# SAM9X75D5MN0 register map
Vendor: Microchip Technology; Series: SAM9X7; File version: 0
Registers are 32-bit, read-write, reset 0x0 unless marked. A register's access mark holds for its fields unless they carry their own. Offsets are from the block's base; [hi:lo] are bit positions; {n}, {i} and the like mark numbered series; 'fields as' and 'values as' point back to an identical list.

## SDMMC0 — Secure Digital MultiMedia Card Controller
Base 0x80000000; register names take the prefix SDMMC_
Same registers: SDMMC1 0x90000000
0x00 SSAR — SDMA System Address / Argument 2 Register
  [31:0] ADDR — SDMA System Address
0x00 SSAR_CMD23_MODE (alternate view of SSAR) — SDMA System Address / Argument 2 Register
  [31:0] ARG2 — SDMA Argument 2
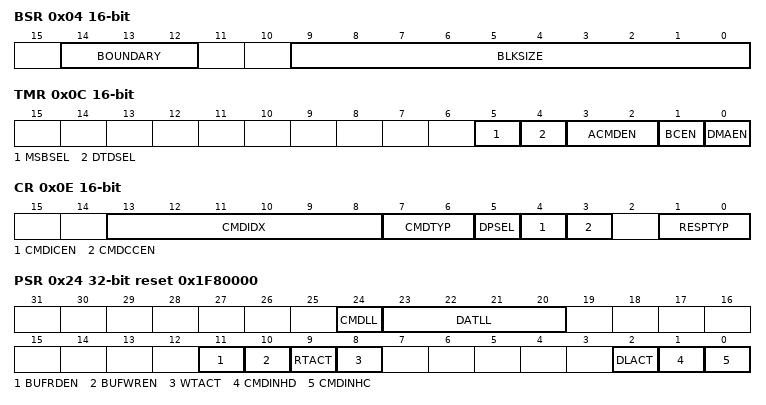
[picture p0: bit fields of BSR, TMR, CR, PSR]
0x04 BSR 16-bit — Block Size Register
  [14:12] BOUNDARY — SDMA Buffer Boundary
    0=4K (4-Kbyte boundary); 1=8K (8-Kbyte boundary); 2=16K (16-Kbyte boundary); 3=32K (32-Kbyte boundary); 4=64K (64-Kbyte boundary); 5=128K (128-Kbyte boundary); 6=256-Kbyte boundary; 7=512K (512-Kbyte boundary)
  [9:0] BLKSIZE — Transfer Block Size
0x06 BCR 16-bit — Block Count Register
  [15:0] BLKCNT — Block Count for Current Transfer
0x08 ARG1R — Argument 1 Register
  [31:0] ARG1 — Argument 1
0x0C TMR 16-bit — Transfer Mode Register
  [5] MSBSEL — Multi/Single Block Selection
  [4] DTDSEL — Data Transfer Direction Selection
    0=WRITE (Writes data from the SDMMC to the device.); 1=READ (Reads data from the device to the SDMMC.)
  [3:2] ACMDEN — Auto Command Enable
    0=DISABLED (Auto Command Disabled); 1=CMD12 (Auto CMD12 Enabled); 2=CMD23 (Auto CMD23 Enabled)
  [1] BCEN — Block Count Enable
    0=DISABLED (Block count is disabled.); 1=ENABLED (Block count is enabled.)
  [0] DMAEN — DMA Enable
    0=DISABLED (DMA functionality is disabled.); 1=ENABLED (DMA functionality is enabled.)
0x0E CR 16-bit — Command Register
  [13:8] CMDIDX — Command Index
  [7:6] CMDTYP — Command Type
    0=NORMAL (Other commands); 1=SUSPEND (CMD52 to write 'Bus Suspend' in the Card Common Control Registers (CCCR) (for SDIO only)); 2=RESUME (CMD52 to write 'Function Select' in the Card Common Control Registers (CCCR) (for SDIO only)); 3=ABORT (CMD12, CMD52 to write 'I/O Abort' in the Card Common Control Registers (CCCR) (for SDIO only))
  [5] DPSEL — Data Present Select
    0=No data present; 1=Data present
  [4] CMDICEN — Command Index Check Enable
    0=DISABLED (The Command Index Check is disabled.); 1=ENABLED (The Command Index Check is enabled.)
  [3] CMDCCEN — Command CRC Check Enable
    0=DISABLED (The Command CRC Check is disabled.); 1=ENABLED (The Command CRC Check is enabled.)
  [1:0] RESPTYP — Response Type
    0=NORESP (No Response); 1=RL136 (Response Length 136); 2=RL48 (Response Length 48); 3=RL48BUSY (Response Length 48 with Busy)
{0x10+4i} RR[{i}] (i=0..3) ro — Response Register x
  [31:0] CMDRESP — Command Response
0x20 BDPR — Buffer Data Port Register
  [31:0] BUFDATA — Buffer Data
0x24 PSR ro reset 0x1F80000 — Present State Register
  [24] CMDLL — CMD Line Level
  [23:20] DATLL — DAT[3:0] Line Level
  [11] BUFRDEN — Buffer Read Enable
  [10] BUFWREN — Buffer Write Enable
  [9] RTACT — Read Transfer Active
  [8] WTACT — Write Transfer Active
  [2] DLACT — DAT Line Active
    0=DAT line inactive; 1=DAT line active
  [1] CMDINHD — Command Inhibit (DAT)
    0=Can issue a command which uses the DAT line(s); 1=Cannot issue a command which uses the DAT line(s)
  [0] CMDINHC — Command Inhibit (CMD)
    0=Can issue a command using only CMD line; 1=Cannot issue a command
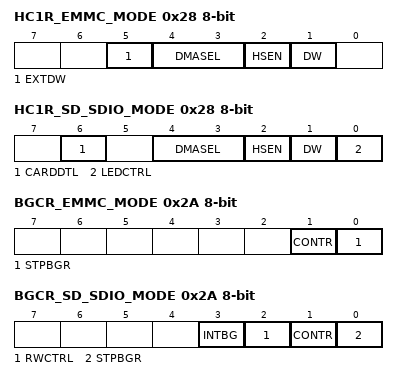
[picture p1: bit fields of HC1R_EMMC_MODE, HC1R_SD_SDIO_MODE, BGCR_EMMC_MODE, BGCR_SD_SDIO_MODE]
0x28 HC1R_EMMC_MODE 8-bit — Host Control 1 Register
  [5] EXTDW — Extended Data Width
  [4:3] DMASEL — DMA Select
    0=SDMA (SDMA is selected); 2=ADMA32 (32-bit Address ADMA2 is selected)
  [2] HSEN — High Speed Enable
  [1] DW — Data Width
    0=_1_BIT (1-bit mode.); 1=_4_BIT (4-bit mode.)
0x28 HC1R_SD_SDIO_MODE 8-bit (alternate view of HC1R_EMMC_MODE) — Host Control 1 Register
  [6] CARDDTL — Card Detect Test Level
    0=No card; 1=Card inserted
  [4:3] DMASEL — DMA Select
    values as HC1R_EMMC_MODE.DMASEL
  [2] HSEN — High Speed Enable
    0=Normal Speed mode; 1=High Speed mode
  [1] DW — Data Width
    0=1_BIT (1-bit mode.); 1=4_BIT (4-bit mode.)
  [0] LEDCTRL — LED Control
    0=OFF (LED off.); 1=ON (LED on.)
0x29 PCR 8-bit reset 0xE — Power Control Register
  [0] SDBPWR — SD Bus Power
0x2A BGCR_EMMC_MODE 8-bit — Block Gap Control Register
  [1] CONTR — Continue Request
    0=No effect; 1=Restart
  [0] STPBGR — Stop At Block Gap Request
    0=Transfer; 1=Stop
0x2A BGCR_SD_SDIO_MODE 8-bit (alternate view of BGCR_EMMC_MODE) — Block Gap Control Register
  [3] INTBG — Interrupt at Block Gap
    0=DISABLED (Interrupt detection disabled.); 1=ENABLED (Interrupt detection enabled.)
  [2] RWCTRL — Read Wait Control
    0=Disables Read Wait control; 1=Enables Read Wait control
  [1] CONTR — Continue Request
    0=No effect; 1=Restart
  [0] STPBGR — Stop At Block Gap Request
    0=Transfer; 1=Stop
0x2B WCR 8-bit — Wakeup Control Register
  [0] WKENCINT — Wakeup Event Enable on Card Interrupt
    0=DISABLED (Wakeup Event disabled.); 1=ENABLED (Wakeup Event enabled.)
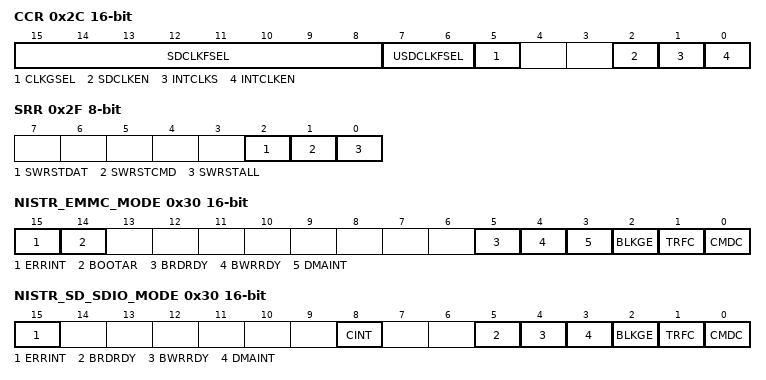
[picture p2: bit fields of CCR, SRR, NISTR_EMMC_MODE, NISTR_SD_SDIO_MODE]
0x2C CCR 16-bit — Clock Control Register
  [15:8] SDCLKFSEL — SDCLK Frequency Select
  [7:6] USDCLKFSEL — Upper Bits of SDCLK Frequency Select
  [5] CLKGSEL — Clock Generator Select
    0=Divided Clock mode (BASECLK is used to generate SDCLK); 1=Programmable Clock mode (MULTCLK is used to generate SDCLK)
  [2] SDCLKEN — SD Clock Enable
    0=SD Clock disabled; 1=SD Clock enabled
  [1] INTCLKS — Internal Clock Stable
    0=Internal clock not ready; 1=Internal clock ready
  [0] INTCLKEN — Internal Clock Enable
    0=The internal clock stops; 1=The internal clock oscillates
0x2E TCR 8-bit — Timeout Control Register
  [3:0] DTCVAL — Data Timeout Counter Value
0x2F SRR 8-bit — Software Reset Register
  [all] fields
    0=Work; 1=Reset
  [2] SWRSTDAT — Software reset for DAT line
  [1] SWRSTCMD — Software reset for CMD line
  [0] SWRSTALL — Software reset for All
0x30 NISTR_EMMC_MODE 16-bit — Normal Interrupt Status Register
  [15] ERRINT — Error Interrupt
    0=No error; 1=Error
  [14] BOOTAR — Boot Acknowledge Received
    0=Boot Acknowledge pattern not received; 1=Boot Acknowledge pattern received
  [5] BRDRDY — Buffer Read Ready
    0=Not ready to read buffer; 1=Ready to read buffer
  [4] BWRRDY — Buffer Write Ready
    0=Not ready to write buffer; 1=Ready to write buffer
  [3] DMAINT — DMA Interrupt
    0=No DMA interrupt; 1=DMA interrupt
  [2] BLKGE — Block Gap Event
  [1] TRFC — Transfer Complete
    0=Command execution is not complete; 1=Command execution is complete
  [0] CMDC — Command Complete
0x30 NISTR_SD_SDIO_MODE 16-bit (alternate view of NISTR_EMMC_MODE) — Normal Interrupt Status Register
  [15] ERRINT — Error Interrupt
  [8] CINT — Card Interrupt
    0=No card interrupt; 1=Card interrupt
  [5] BRDRDY — Buffer Read Ready
  [4] BWRRDY — Buffer Write Ready
  [3] DMAINT — DMA Interrupt
    0=No DMA Interrupt; 1=DMA Interrupt
  [2] BLKGE — Block Gap Event
    0=No block gap event; 1=Transaction stopped at block gap
  [1] TRFC — Transfer Complete
    values as NISTR_EMMC_MODE.TRFC
  [0] CMDC — Command Complete
    0=No command complete; 1=Command complete
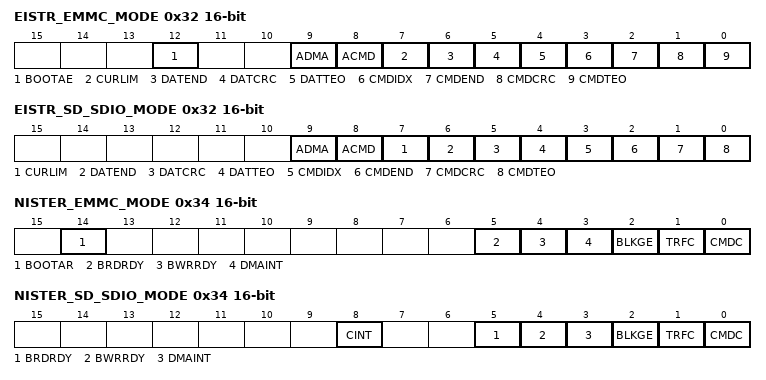
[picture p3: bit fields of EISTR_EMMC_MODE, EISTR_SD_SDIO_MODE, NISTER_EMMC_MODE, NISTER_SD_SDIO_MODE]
0x32 EISTR_EMMC_MODE 16-bit — Error Interrupt Status Register
  [12] BOOTAE — Boot Acknowledge Error
    0=No error; 1=Error
  [9] ADMA — ADMA Error
    0=No error; 1=Error
  [8] ACMD — Auto CMD Error
    0=No error; 1=Error
  [7] CURLIM — Current Limit Error
    0=No error; 1=Error
  [6] DATEND — Data End Bit Error
    0=No error; 1=Error
  [5] DATCRC — Data CRC Error
    0=No error; 1=Error
  [4] DATTEO — Data Timeout error
    0=No error; 1=Error
  [3] CMDIDX — Command Index Error
  [2] CMDEND — Command End Bit Error
  [1] CMDCRC — Command CRC Error
  [0] CMDTEO — Command Timeout Error
0x32 EISTR_SD_SDIO_MODE 16-bit (alternate view of EISTR_EMMC_MODE) — Error Interrupt Status Register
  [9] ADMA — ADMA Error
  [8] ACMD — Auto CMD Error
  [7] CURLIM — Current Limit Error
  [6] DATEND — Data End Bit Error
  [5] DATCRC — Data CRC error
    0=No error; 1=Error
  [4] DATTEO — Data Timeout Error
    0=No error; 1=Error
  [3] CMDIDX — Command Index Error
    0=No error; 1=Error
  [2] CMDEND — Command End Bit Error
    0=No error; 1=Error
  [1] CMDCRC — Command CRC Error
  [0] CMDTEO — Command Timeout Error
0x34 NISTER_EMMC_MODE 16-bit — Normal Interrupt Status Enable Register
  [14] BOOTAR — Boot Acknowledge Received Status Enable
    0=MASKED (The BOOTAR status flag in SDMMC_NISTR is masked.); 1=ENABLED (The BOOTAR status flag in SDMMC_NISTR is enabled.)
  [5] BRDRDY — Buffer Read Ready Status Enable
    0=MASKED (The BRDRDY status flag in SDMMC_NISTR is masked.); 1=ENABLED (The BRDRDY status flag in SDMMC_NISTR is enabled.)
  [4] BWRRDY — Buffer Write Ready Status Enable
    0=MASKED (The BWRRDY status flag in SDMMC_NISTR is masked.); 1=ENABLED (The BWRRDY status flag in SDMMC_NISTR is enabled.)
  [3] DMAINT — DMA Interrupt Status Enable
    0=MASKED (The DMAINT status flag in SDMMC_NISTR is masked.); 1=ENABLED (The DMAINT status flag in SDMMC_NISTR is enabled.)
  [2] BLKGE — Block Gap Event Status Enable
    0=MASKED (The BLKGE status flag in SDMMC_NISTR is masked.); 1=ENABLED (The BLKGE status flag in SDMMC_NISTR is enabled.)
  [1] TRFC — Transfer Complete Status Enable
    0=MASKED (The TRFC status flag in SDMMC_NISTR is masked.); 1=ENABLED (The TRFC status flag in SDMMC_NISTR is enabled.)
  [0] CMDC — Command Complete Status Enable
    0=MASKED (The CMDC status flag in SDMMC_NISTR is masked.); 1=ENABLED (The CMDC status flag in SDMMC_NISTR is enabled.)
0x34 NISTER_SD_SDIO_MODE 16-bit (alternate view of NISTER_EMMC_MODE) — Normal Interrupt Status Enable Register
  [8] CINT — Card Interrupt Status Enable
    0=MASKED (The CINT status flag in SDMMC_NISTR is masked.); 1=ENABLED (The CINT status flag in SDMMC_NISTR is enabled.)
  [5] BRDRDY — Buffer Read Ready Status Enable
    values as NISTER_EMMC_MODE.BRDRDY
  [4] BWRRDY — Buffer Write Ready Status Enable
    values as NISTER_EMMC_MODE.BWRRDY
  [3] DMAINT — DMA Interrupt Status Enable
    values as NISTER_EMMC_MODE.DMAINT
  [2] BLKGE — Block Gap Event Status Enable
    values as NISTER_EMMC_MODE.BLKGE
  [1] TRFC — Transfer Complete Status Enable
    values as NISTER_EMMC_MODE.TRFC
  [0] CMDC — Command Complete Status Enable
    values as NISTER_EMMC_MODE.CMDC
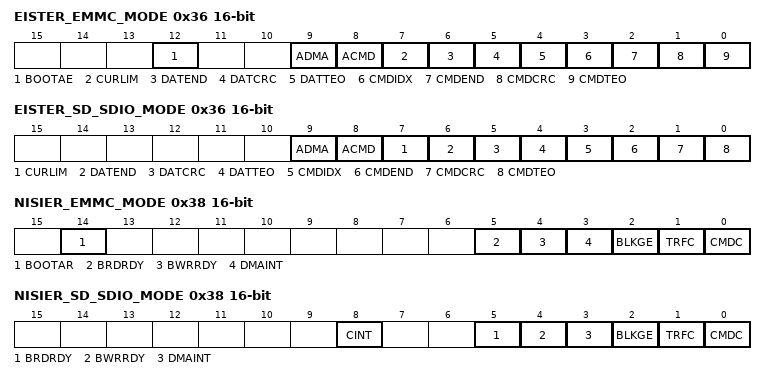
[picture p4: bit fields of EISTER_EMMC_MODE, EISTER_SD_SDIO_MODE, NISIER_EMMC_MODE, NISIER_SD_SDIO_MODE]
0x36 EISTER_EMMC_MODE 16-bit — Error Interrupt Status Enable Register
  [12] BOOTAE — Boot Acknowledge Error Status Enable
    0=MASKED (The BOOTAE status flag in SDMMC_EISTR is masked.); 1=ENABLED (The BOOTAE status flag in SDMMC_EISTR is enabled.)
  [9] ADMA — ADMA Error Status Enable
    0=MASKED (The ADMA status flag in SDMMC_EISTR is masked.); 1=ENABLED (The ADMA status flag in SDMMC_EISTR is enabled.)
  [8] ACMD — Auto CMD Error Status Enable
    0=MASKED (The ACMD status flag in SDMMC_EISTR is masked.); 1=ENABLED (The ACMD status flag in SDMMC_EISTR is enabled.)
  [7] CURLIM — Current Limit Error Status Enable
    0=MASKED (The CURLIM status flag in SDMMC_EISTR is masked.); 1=ENABLED (The CURLIM status flag in SDMMC_EISTR is enabled.)
  [6] DATEND — Data End Bit Error Status Enable
    0=MASKED (The DATEND status flag in SDMMC_EISTR is masked.); 1=ENABLED (The DATEND status flag in SDMMC_EISTR is enabled.)
  [5] DATCRC — Data CRC Error Status Enable
    0=MASKED (The DATCRC status flag in SDMMC_EISTR is masked.); 1=ENABLED (The DATCRC status flag in SDMMC_EISTR is enabled.)
  [4] DATTEO — Data Timeout Error Status Enable
    0=MASKED (The DATTEO status flag in SDMMC_EISTR is masked.); 1=ENABLED (The DATTEO status flag in SDMMC_EISTR is enabled.)
  [3] CMDIDX — Command Index Error Status Enable
    0=MASKED (The CMDIDX status flag in SDMMC_EISTR is masked.); 1=ENABLED (The CMDIDX status flag in SDMMC_EISTR is enabled.)
  [2] CMDEND — Command End Bit Error Status Enable
    0=MASKED (The CMDEND status flag in SDMMC_EISTR is masked.); 1=ENABLED (The CMDEND status flag in SDMMC_EISTR is enabled.)
  [1] CMDCRC — Command CRC Error Status Enable
    0=MASKED (The CMDCRC status flag in SDMMC_EISTR is masked.); 1=ENABLED (The CMDCRC status flag in SDMMC_EISTR is enabled.)
  [0] CMDTEO — Command Timeout Error Status Enable
    0=MASKED (The CMDTEO status flag in SDMMC_EISTR is masked.); 1=ENABLED (The CMDTEO status flag in SDMMC_EISTR is enabled.)
0x36 EISTER_SD_SDIO_MODE 16-bit (alternate view of EISTER_EMMC_MODE) — Error Interrupt Status Enable Register
  [9] ADMA — ADMA Error Status Enable
    values as EISTER_EMMC_MODE.ADMA
  [8] ACMD — Auto CMD Error Status Enable
    values as EISTER_EMMC_MODE.ACMD
  [7] CURLIM — Current Limit Error Status Enable
    values as EISTER_EMMC_MODE.CURLIM
  [6] DATEND — Data End Bit Error Status Enable
    values as EISTER_EMMC_MODE.DATEND
  [5] DATCRC — Data CRC Error Status Enable
    values as EISTER_EMMC_MODE.DATCRC
  [4] DATTEO — Data Timeout Error Status Enable
    values as EISTER_EMMC_MODE.DATTEO
  [3] CMDIDX — Command Index Error Status Enable
    values as EISTER_EMMC_MODE.CMDIDX
  [2] CMDEND — Command End Bit Error Status Enable
    values as EISTER_EMMC_MODE.CMDEND
  [1] CMDCRC — Command CRC Error Status Enable
    values as EISTER_EMMC_MODE.CMDCRC
  [0] CMDTEO — Command Timeout Error Status Enable
    values as EISTER_EMMC_MODE.CMDTEO
0x38 NISIER_EMMC_MODE 16-bit — Normal Interrupt Signal Enable Register
  [14] BOOTAR — Boot Acknowledge Received Signal Enable
    0=MASKED (No interrupt is generated when the BOOTAR status rises in SDMMC_NISTR.); 1=ENABLED (An interrupt is generated when the BOOTAR status rises in SDMMC_NISTR.)
  [5] BRDRDY — Buffer Read Ready Signal Enable
    0=MASKED (No interrupt is generated when the BRDRDY status rises in SDMMC_NISTR.); 1=ENABLED (An interrupt is generated when the BRDRDY status rises in SDMMC_NISTR.)
  [4] BWRRDY — Buffer Write Ready Signal Enable
    0=MASKED (No interrupt is generated when the BWRRDY status rises in SDMMC_NISTR.); 1=ENABLED (An interrupt is generated when the BWRRDY status rises in SDMMC_NISTR.)
  [3] DMAINT — DMA Interrupt Signal Enable
    0=MASKED (No interrupt is generated when the DMAINT status rises in SDMMC_NISTR.); 1=ENABLED (An interrupt is generated when the DMAINT status rises in SDMMC_NISTR.)
  [2] BLKGE — Block Gap Event Signal Enable
    0=MASKED (No interrupt is generated when the BLKGE status rises in SDMMC_NISTR.); 1=ENABLED (An interrupt is generated when the BLKGE status rises in SDMMC_NISTR.)
  [1] TRFC — Transfer Complete Signal Enable
    0=MASKED (No interrupt is generated when the TRFC status rises in SDMMC_NISTR.); 1=ENABLED (An interrupt is generated when the TRFC status rises in SDMMC_NISTR.)
  [0] CMDC — Command Complete Signal Enable
    0=MASKED (No interrupt is generated when the CMDC status rises in SDMMC_NISTR.); 1=ENABLED (An interrupt is generated when the CMDC status rises in SDMMC_NISTR.)
0x38 NISIER_SD_SDIO_MODE 16-bit (alternate view of NISIER_EMMC_MODE) — Normal Interrupt Signal Enable Register
  [8] CINT — Card Interrupt Signal Enable
    0=MASKED (No interrupt is generated when the CINT status rises in SDMMC_NISTR.); 1=ENABLED (An interrupt is generated when the CINT status rises in SDMMC_NISTR.)
  [5] BRDRDY — Buffer Read Ready Signal Enable
    values as NISIER_EMMC_MODE.BRDRDY
  [4] BWRRDY — Buffer Write Ready Signal Enable
    values as NISIER_EMMC_MODE.BWRRDY
  [3] DMAINT — DMA Interrupt Signal Enable
    values as NISIER_EMMC_MODE.DMAINT
  [2] BLKGE — Block Gap Event Signal Enable
    values as NISIER_EMMC_MODE.BLKGE
  [1] TRFC — Transfer Complete Signal Enable
    values as NISIER_EMMC_MODE.TRFC
  [0] CMDC — Command Complete Signal Enable
    values as NISIER_EMMC_MODE.CMDC
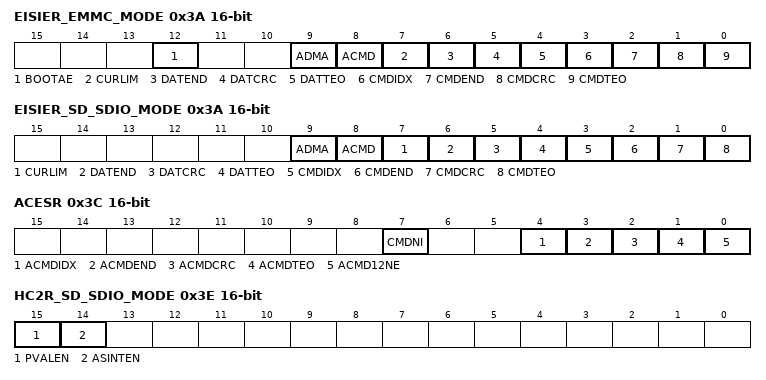
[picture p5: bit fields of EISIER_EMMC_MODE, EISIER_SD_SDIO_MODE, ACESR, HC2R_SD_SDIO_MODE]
0x3A EISIER_EMMC_MODE 16-bit — Error Interrupt Signal Enable Register
  [12] BOOTAE — Boot Acknowledge Error Signal Enable
    0=MASKED (No interrupt is generated when the BOOTAE status rises in SDMMC_EISTR.); 1=ENABLED (An interrupt is generated when the BOOTAE status rises in SDMMC_EISTR.)
  [9] ADMA — ADMA Error Signal Enable
    0=MASKED (No interrupt is generated when the ADMA status rises in SDMMC_EISTR.); 1=ENABLED (An interrupt is generated when the ADMA status rises in SDMMC_EISTR.)
  [8] ACMD — Auto CMD Error Signal Enable
    0=MASKED (No interrupt is generated when the ACMD status rises in SDMMC_EISTR.); 1=ENABLED (An interrupt is generated when the ACMD status rises in SDMMC_EISTR.)
  [7] CURLIM — Current Limit Error Signal Enable
    0=MASKED (No interrupt is generated when the CURLIM status rises in SDMMC_EISTR.); 1=ENABLED (An interrupt is generated when the CURLIM status rises in SDMMC_EISTR.)
  [6] DATEND — Data End Bit Error Signal Enable
    0=MASKED (No interrupt is generated when the DATEND status rises in SDMMC_EISTR.); 1=ENABLED (An interrupt is generated when the DATEND status rises in SDMMC_EISTR.)
  [5] DATCRC — Data CRC Error Signal Enable
    0=MASKED (No interrupt is generated when the DATCRC status rises in SDMMC_EISTR.); 1=ENABLED (An interrupt is generated when the DATCRC status rises in SDMMC_EISTR.)
  [4] DATTEO — Data Timeout Error Signal Enable
    0=MASKED (No interrupt is generated when the DATTEO status rises in SDMMC_EISTR.); 1=ENABLED (An interrupt is generated when the DATTEO status rises in SDMMC_EISTR.)
  [3] CMDIDX — Command Index Error Signal Enable
    0=MASKED (No interrupt is generated when the CMDIDX status rises in SDMMC_EISTR.); 1=ENABLED (An interrupt is generated when the CMDIDX status rises in SDMMC_EISTR.)
  [2] CMDEND — Command End Bit Error Signal Enable
    0=MASKED (No interrupt is generated when the CMDEND status rises in SDMMC_EISTR.); 1=ENABLED (An interrupt is generated when the CMDEND status rises in SDMMC_EISTR.)
  [1] CMDCRC — Command CRC Error Signal Enable
    0=MASKED (No interrupt is generated when the CDMCRC status rises in SDMMC_EISTR.); 1=ENABLED (An interrupt is generated when the CMDCRC status rises in SDMMC_EISTR.)
  [0] CMDTEO — Command Timeout Error Signal Enable
    0=MASKED (No interrupt is generated when the CMDTEO status rises in SDMMC_EISTR.); 1=ENABLED (An interrupt is generated when the CMDTEO status rises in SDMMC_EISTR.)
0x3A EISIER_SD_SDIO_MODE 16-bit (alternate view of EISIER_EMMC_MODE) — Error Interrupt Signal Enable Register
  [9] ADMA — ADMA Error Signal Enable
    values as EISIER_EMMC_MODE.ADMA
  [8] ACMD — Auto CMD Error Signal Enable
    values as EISIER_EMMC_MODE.ACMD
  [7] CURLIM — Current Limit Error Signal Enable
    values as EISIER_EMMC_MODE.CURLIM
  [6] DATEND — Data End Bit Error Signal Enable
    values as EISIER_EMMC_MODE.DATEND
  [5] DATCRC — Data CRC Error Signal Enable
    values as EISIER_EMMC_MODE.DATCRC
  [4] DATTEO — Data Timeout Error Signal Enable
    values as EISIER_EMMC_MODE.DATTEO
  [3] CMDIDX — Command Index Error Signal Enable
    values as EISIER_EMMC_MODE.CMDIDX
  [2] CMDEND — Command End Bit Error Signal Enable
    values as EISIER_EMMC_MODE.CMDEND
  [1] CMDCRC — Command CRC Error Signal Enable
    values as EISIER_EMMC_MODE.CMDCRC
  [0] CMDTEO — Command Timeout Error Signal Enable
    values as EISIER_EMMC_MODE.CMDTEO
0x3C ACESR 16-bit ro — Auto CMD Error Status Register
  [7] CMDNI — Command Not Issued by Auto CMD12 Error
    0=No error; 1=Error
  [4] ACMDIDX — Auto CMD Index Error
    0=No error; 1=Error
  [3] ACMDEND — Auto CMD End Bit Error
    0=No error; 1=Error
  [2] ACMDCRC — Auto CMD CRC Error
  [1] ACMDTEO — Auto CMD Timeout Error
  [0] ACMD12NE — Auto CMD12 Not Executed
    0=No error; 1=Error
0x3E HC2R_EMMC_MODE 16-bit — Host Control 2 Register
  [15] PVALEN — Preset Value Enable
    0=SDCLK and Driver strength are controlled by the user; 1=Automatic selection by Preset Value is enabled
0x3E HC2R_SD_SDIO_MODE 16-bit (alternate view of HC2R_EMMC_MODE) — Host Control 2 Register
  [15] PVALEN — Preset Value Enable
    values as HC2R_EMMC_MODE.PVALEN
  [14] ASINTEN — Asynchronous Interrupt Enable
    0=Disabled; 1=Enabled
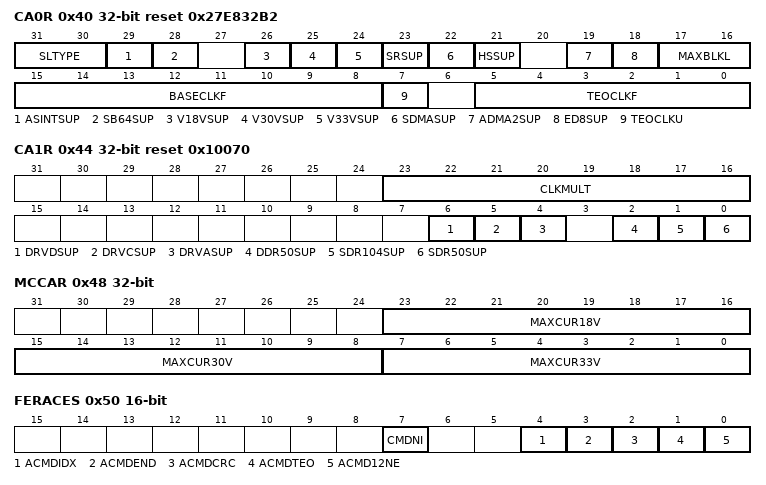
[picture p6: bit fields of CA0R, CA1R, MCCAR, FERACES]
0x40 CA0R reset 0x27E832B2 — Capabilities 0 Register
  [31:30] SLTYPE — Slot Type
    0=REMOVABLECARD (Removable Card Slot); 1=EMBEDDED (Embedded Slot for One Device)
  [29] ASINTSUP — Asynchronous Interrupt Support
    0=Asynchronous interrupt not supported; 1=Asynchronous interrupt supported
  [28] SB64SUP — 64-Bit System Bus Support
    0=64-bit address bus not supported; 1=64-bit address bus supported
  [26] V18VSUP — Voltage Support 1.8V
    0=1.8V Voltage supply not supported; 1=1.8V Voltage supply supported
  [25] V30VSUP — Voltage Support 3.0V
    0=3.0V Voltage supply not supported; 1=3.0V Voltage supply supported
  [24] V33VSUP — Voltage Support 3.3V
    0=3.3V Voltage supply not supported; 1=3.3V Voltage supply supported
  [23] SRSUP — Suspend/Resume Support (read-only)
    0=Suspend/Resume not supported; 1=Suspend/Resume supported
  [22] SDMASUP — SDMA Support (read-only)
    0=SDMA not supported; 1=SDMA supported
  [21] HSSUP — High Speed Support (read-only)
    0=High Speed not supported; 1=High Speed supported
  [19] ADMA2SUP — ADMA2 Support (read-only)
    0=ADMA2 not supported; 1=ADMA2 supported
  [18] ED8SUP — 8-Bit Support for Embedded Device (read-only)
    0=8-bit bus width not supported; 1=8-bit bus width supported
  [17:16] MAXBLKL — Max Block Length (read-only)
    0=512 bytes; 1=1024 bytes; 2=2048 bytes
  [15:8] BASECLKF — Base Clock Frequency
  [7] TEOCLKU — Timeout Clock Unit
    0=KHz; 1=MHz
  [5:0] TEOCLKF — Timeout Clock Frequency
0x44 CA1R reset 0x10070 — Capabilities 1 Register
  [23:16] CLKMULT — Clock Multiplier
  [6] DRVDSUP — Driver Type D Support
    0=Driver type D is not supported; 1=Driver type D is supported
  [5] DRVCSUP — Driver Type C Support
    0=Driver type C is not supported; 1=Driver type C is supported
  [4] DRVASUP — Driver Type A Support
    0=Driver type A is not supported; 1=Driver type A is supported
  [2] DDR50SUP — DDR50 Support
    0=DDR50 mode is not supported; 1=DDR50 mode is supported
  [1] SDR104SUP — SDR104 Support
    0=SDR104 mode is not supported; 1=SDR104 mode is supported
  [0] SDR50SUP — SDR50 Support
    0=SDR50 mode is not supported; 1=SDR50 mode is supported
0x48 MCCAR — Maximum Current Capabilities Register
  [23:16] MAXCUR18V — Maximum Current for 1.8V
  [15:8] MAXCUR30V — Maximum Current for 3.0V
  [7:0] MAXCUR33V — Maximum Current for 3.3V
0x50 FERACES 16-bit wo — Force Event Register for Auto CMD Error Status
  [7] CMDNI — Force Event for Command Not Issued by Auto CMD12 Error
  [4] ACMDIDX — Force Event for Auto CMD Index Error
  [3] ACMDEND — Force Event for Auto CMD End Bit Error
  [2] ACMDCRC — Force Event for Auto CMD CRC Error
  [1] ACMDTEO — Force Event for Auto CMD Timeout Error
  [0] ACMD12NE — Force Event for Auto CMD12 Not Executed
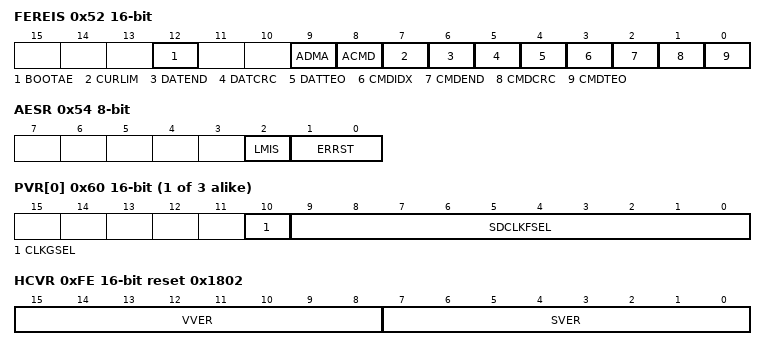
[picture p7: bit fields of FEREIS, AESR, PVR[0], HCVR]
0x52 FEREIS 16-bit wo — Force Event Register for Error Interrupt Status
  [12] BOOTAE — Force Event for Boot Acknowledge Error
  [9] ADMA — Force Event for ADMA Error
  [8] ACMD — Force Event for Auto CMD Error
  [7] CURLIM — Force Event for Current Limit Error
  [6] DATEND — Force Event for Data End Bit Error
  [5] DATCRC — Force Event for Data CRC error
  [4] DATTEO — Force Event for Data Timeout error
  [3] CMDIDX — Force Event for Command Index Error
  [2] CMDEND — Force Event for Command End Bit Error
  [1] CMDCRC — Force Event for Command CRC Error
  [0] CMDTEO — Force Event for Command Timeout Error
0x54 AESR 8-bit ro — ADMA Error Status Register
  [2] LMIS — ADMA Length Mismatch Error
    0=No error; 1=Error
  [1:0] ERRST — ADMA Error State
    0=STOP ((Stop DMA) SDMMC_ASAR points to the descriptor following the error descriptor); 1=FDS ((Fetch Descriptor) SDMMC_ASAR points to the error descriptor); 3=TFR ((Transfer Data) SDMMC_ASAR points to the descriptor following the error descriptor)
0x58 ASAR0 — ADMA System Address Register 0
  [31:0] ADMASA — ADMA System Address
{0x60+2i} PVR[{i}] (i=0..2) 16-bit — Preset Value Register x (for initialization)
  [10] CLKGSEL — Clock Generator Select
  [9:0] SDCLKFSEL — SDCLK Frequency Select
0xFC SISR 16-bit ro — Slot Interrupt Status Register
  [1:0] INTSSL — Interrupt Signal for Each Slot
0xFE HCVR 16-bit ro reset 0x1802 — Host Controller Version Register
  [15:8] VVER — Vendor Version Number
  [7:0] SVER — Specification Version Number
    0=SD1 (SD Host Specification Version 1.00); 1=SD2 (SD Host Specification Version 2.00, including the feature of the ADMA and Test Register); 2=SD3 (SD Host Specification Version 3.00)
0x200 APSR ro reset 0xF — Additional Present State Register
  [3:0] HDATLL — DAT[7:4] High Line Level
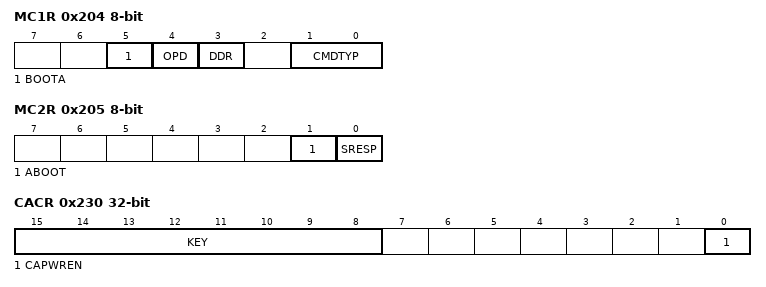
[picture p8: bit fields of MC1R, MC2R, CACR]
0x204 MC1R 8-bit — e.MMC Control 1 Register
  [5] BOOTA — e.MMC Boot Acknowledge Enable
  [4] OPD — e.MMC Open Drain Mode
    0=The command line is in push-pull; 1=The command line is in open drain
  [3] DDR — e.MMC HSDDR Mode
    0=High Speed DDR is not selected; 1=High Speed DDR is selected
  [1:0] CMDTYP — e.MMC Command Type
    0=NORMAL (The command is not an e.MMC specific command.); 1=WAITIRQ (This bit must be set to 1 when the e.MMC is in Interrupt mode (CMD40). See 'Interrupt Mode' in the Embedded MultiMedia Card (e.MMC) Electrical Standard 4.51.); 2=STREAM (This bit must be set to 1 in the case of Stream Read(CMD11) or Stream Write (CMD20). Only effective for e.MMC up to revision 4.41.); 3=BOOT (Starts a Boot Operation mode at the next write to SDMMC_CR. Boot data are read directly from e.MMC device.)
0x205 MC2R 8-bit wo — e.MMC Control 2 Register
  [1] ABOOT — e.MMC Abort Boot
  [0] SRESP — e.MMC Abort Wait IRQ
0x208 ACR — AHB Control Register
  [1:0] BMAX — AHB Maximum Burst
    0=INCR16 (The maximum burst size is INCR16.); 1=INCR8 (The maximum burst size is INCR8.); 2=INCR4 (The maximum burst size is INCR4.); 3=SINGLE (Only SINGLE transfers are performed.)
0x20C CC2R — Clock Control 2 Register
  [0] FSDCLKD — Force SDCLK Disabled
    0=The SDCLK is forced and it cannot be stopped immediately after the transaction; 1=The SDCLK is not forced and it can be stopped immediately after the transaction
0x230 CACR — Capabilities Control Register
  [15:8] KEY
    70=KEY (Writing any other value in this field aborts the write operation of the CAPWREN bit. Always reads as 0.)
  [0] CAPWREN — Capabilities Write Enable
    0=Capabilities registers (SDMMC_CA0R, SDMMC_CA1R and SDMMC_MCCAR) cannot be written; 1=Capabilities registers (SDMMC_CA0R, SDMMC_CA1R and SDMMC_MCCAR) can be written
0x234 DBGR — Debug Register
  [0] NIDBG — Nonintrusive Debug
    0=DISABLED (Reading the SDMMC_BDPR via debugger increments the dual port RAM read pointer.); 1=ENABLED (Reading the SDMMC_BDPR via debugger does not increment the dual port RAM read pointer.)
